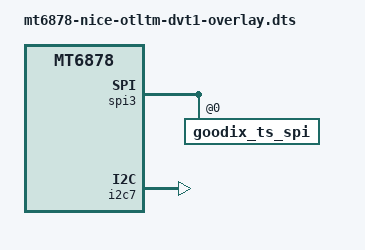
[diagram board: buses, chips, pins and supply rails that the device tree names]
/* Copyright (c) 2023, Motorola Mobility Inc. All rights reserved.
 *
 * This program is free software; you can redistribute it and/or modify
 * it under the terms of the GNU General Public License version 2 and
 * only version 2 as published by the Free Software Foundation.
 *
 * This program is distributed in the hope that it will be useful,
 * but WITHOUT ANY WARRANTY; without even the implied warranty of
 * MERCHANTABILITY or FITNESS FOR A PARTICULAR PURPOSE.  See the
 * GNU General Public License for more details.
 */

/dts-v1/;
/plugin/;

#include "mediatek/mt6878-nice-common-overlay.dtsi"

#define NICE_OTLTM_RADIO 7
/* Board match root node */
/ {
	fragment@model {
		target-path = "/";
		__overlay__ {
			mot,model = "nice";
			mot,board-id = <(NICE_OTLTM_RADIO << 8 | 0x4B) 0xB100>;
		};
	};
};

&st21nfc {
	/*clkreq-gpios = <&pio 152 0x0>;*/
};

&spi3 {
	goodix_ts_spi@0 {
		/*goodix,iovdd-gpio = <&pio 151 0x0>;*/
	};
};

&mt6375_typec {
	mmi,support_CID;
        tcpc,en_wd;
	mmi_cid_int = <&pio 37 0x0>;
};

&mt6375_chg {
	mmi,hvdcp-support;
};

&i2c7 {
	status = "okay";
	wt6670f@35 {
		status = "disabled";
	};
};

#include <nice_evb/cust.dtsi>
/*End of this file, DO NOT ADD ANYTHING HERE*/
